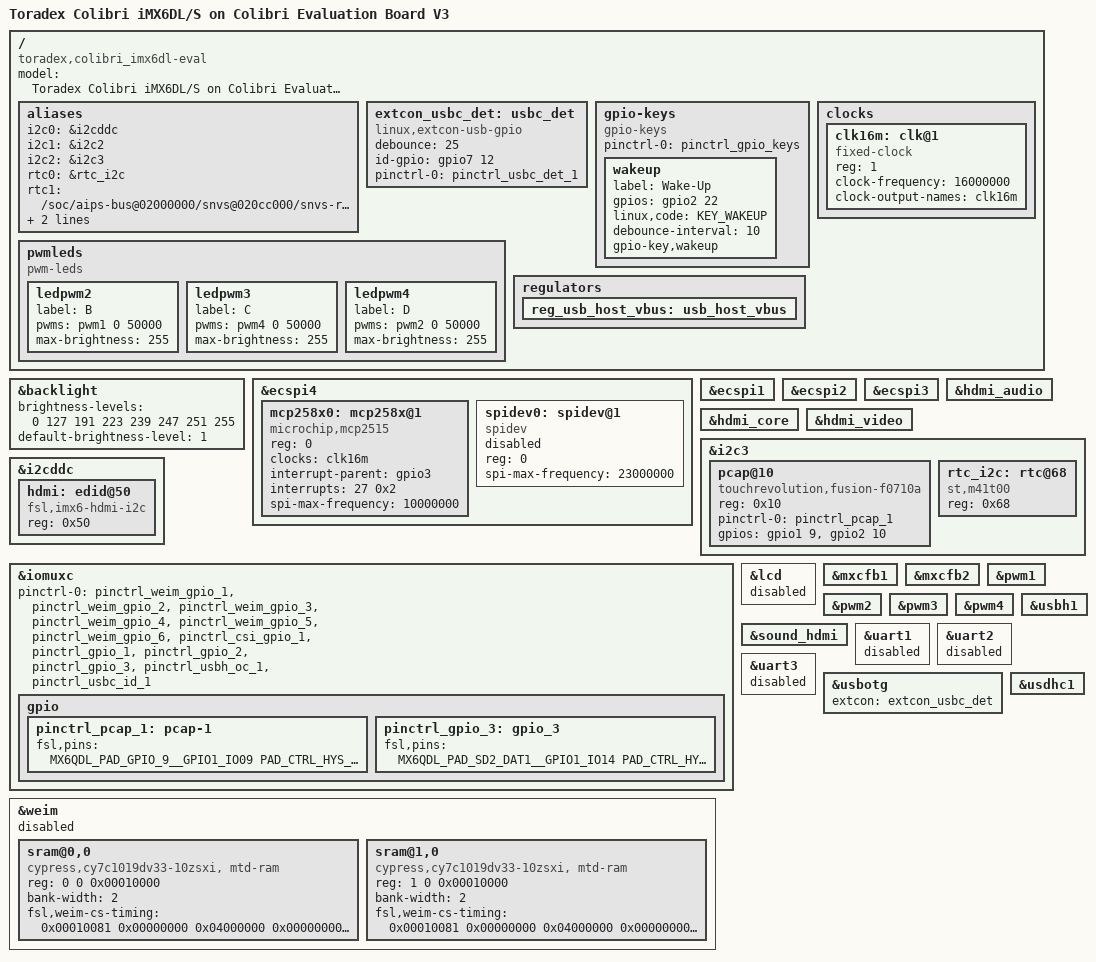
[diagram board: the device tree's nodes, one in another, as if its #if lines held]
/*
 * Copyright 2014-2015 Toradex AG
 * Copyright 2012 Freescale Semiconductor, Inc.
 * Copyright 2011 Linaro Ltd.
 *
 * The code contained herein is licensed under the GNU General Public
 * License. You may obtain a copy of the GNU General Public License
 * Version 2 or later at the following locations:
 *
 * http://www.opensource.org/licenses/gpl-license.html
 * http://www.gnu.org/copyleft/gpl.html
 */

/dts-v1/;

#include <dt-bindings/input/input.h>
#include <dt-bindings/interrupt-controller/irq.h>
#include "imx6dl.dtsi"
#include "imx6qdl-colibri.dtsi"

/* Add the following define if you connect a Fusion display with a capacitive
   touch controller */
/* #define PCAP */

/ {
	model = "Toradex Colibri iMX6DL/S on Colibri Evaluation Board V3";
	compatible = "toradex,colibri_imx6dl-eval", "toradex,colibri_imx6dl", "fsl,imx6dl";

	aliases {
		i2c0 = &i2cddc;
		i2c1 = &i2c2;
		i2c2 = &i2c3;
	};

	aliases {
		rtc0 = &rtc_i2c;
		rtc1 = "/soc/aips-bus@02000000/snvs@020cc000/snvs-rtc-lp@34";
	};

	aliases {
		/* the following, together with kernel patches, forces a fixed assignment
		   between device id and usdhc controller */
		/* i.e. the eMMC on usdhc3 will be /dev/mmcblk0 */
		mmc0 = &usdhc3; /* eMMC */
		mmc1 = &usdhc1; /* MMC 4bit slot */
	};

	extcon_usbc_det: usbc_det {
		compatible = "linux,extcon-usb-gpio";
		debounce = <25>;
		id-gpio = <&gpio7 12 GPIO_ACTIVE_HIGH>;
		pinctrl-names = "default";
		pinctrl-0 = <&pinctrl_usbc_det_1>;
	};

	gpio-keys {
		compatible = "gpio-keys";
		pinctrl-names = "default";
		pinctrl-0 = <&pinctrl_gpio_keys>;

		wakeup {
			label = "Wake-Up";
			gpios = <&gpio2 22 GPIO_ACTIVE_HIGH>;
			linux,code = <KEY_WAKEUP>;
			debounce-interval = <10>;
			gpio-key,wakeup;
		};
	};

	pwmleds {
		compatible = "pwm-leds";
#ifndef PCAP
		ledpwm2 {
			label = "PWM<B>";
			pwms = <&pwm1 0 50000>;
			max-brightness = <255>;
		};

		ledpwm3 {
			label = "PWM<C>";
			pwms = <&pwm4 0 50000>;
			max-brightness = <255>;
		};
#endif
		ledpwm4 {
			label = "PWM<D>";
			pwms = <&pwm2 0 50000>;
			max-brightness = <255>;
		};
	};

	regulators {
		reg_usb_host_vbus: usb_host_vbus {
			status = "okay";
		};
	};
};

&backlight {
#if 0 /* PWM polarity: if 1 is brightest */
#if 0 /* Fusion 7 needs 10kHz PWM frequency */
	pwms = <&pwm3 0 100000>;
#endif
	brightness-levels = <0 4 8 16 32 64 128 255>;
	default-brightness-level = <6>;
#else /* PWM plarity: if 0 is brightest */
	brightness-levels = <0 127 191 223 239 247 251 255>;
	default-brightness-level = <1>;
#endif
	status = "okay";
};

/ {
	clocks {
		/* fixed crystal dedicated to mpc258x */
		clk16m: clk@1 {
			compatible = "fixed-clock";
			reg=<1>;
			#clock-cells = <0>;
			clock-frequency = <16000000>;
			clock-output-names = "clk16m";
		};
	};
};

/* Colibri SPI */
&ecspi4 {
	status = "okay";
	mcp258x0: mcp258x@1 {
		compatible = "microchip,mcp2515";
		reg = <0>;
		clocks = <&clk16m>;
		interrupt-parent = <&gpio3>;
		interrupts = <27 0x2>;
		spi-max-frequency = <10000000>;
		status = "okay";
	};
	spidev0: spidev@1 {
		compatible = "spidev";
		reg = <0>;
		spi-max-frequency = <23000000>;
		status = "disabled";
	};
};
/* connect device to additional SPI bus */
&ecspi1 {
 status = "okay";
};
&ecspi2 {
 status = "okay";
};
&ecspi3 {
 status = "okay";
};


&hdmi_audio {
	status = "okay";
};

&hdmi_core {
	status = "okay";
};

&hdmi_video {
	status = "okay";
};


/*
 * I2C: I2C3_SDA/SCL on SODIMM 194/196 (e.g. RTC on carrier
 * board)
 */
&i2c3 {
	status = "okay";
#ifdef PCAP /* not standard pinout, disable PWM<B>, PWM<C> */
	pcap@10 {
		/* TouchRevolution Fusion 7 and 10 multi-touch controller */
		compatible = "touchrevolution,fusion-f0710a";
		reg = <0x10>;
		pinctrl-names = "default";
		pinctrl-0 = <&pinctrl_pcap_1>;
		gpios = <&gpio1  9 0 /* SODIMM 28, Pen down interrupt */
			 &gpio2 10 0 /* SODIMM 30, Reset */
			>;
	};
#endif
	/* M41T0M6 real time clock on carrier board */
	rtc_i2c: rtc@68 {
		compatible = "st,m41t00";
		reg = <0x68>;
	};
};

/*
 * DDC_I2C: I2C2_SDA/SCL on extension connector pin 15/16
 */
&i2cddc {
	status = "okay";

	hdmi: edid@50 {
		compatible = "fsl,imx6-hdmi-i2c";
		reg = <0x50>;
	};
};

&iomuxc {
	/*
	 * Mux all pins which are unused to be GPIOs
	 * so they are ready for export to user space
	 */
	pinctrl-names = "default";
	pinctrl-0 = <&pinctrl_weim_gpio_1 &pinctrl_weim_gpio_2
	             &pinctrl_weim_gpio_3 &pinctrl_weim_gpio_4
	             &pinctrl_weim_gpio_5 &pinctrl_weim_gpio_6
	             &pinctrl_csi_gpio_1
	             &pinctrl_gpio_1
	             &pinctrl_gpio_2 /*may cause conflict with can1*/
               &pinctrl_gpio_3  /*THIS NODE IS DEFINED BY ME*/
	             &pinctrl_usbh_oc_1 &pinctrl_usbc_id_1>;

	gpio {
		pinctrl_pcap_1: pcap-1 {
			fsl,pins = <
				MX6QDL_PAD_GPIO_9__GPIO1_IO09	PAD_CTRL_HYS_PD /* SODIMM 28 */
				MX6QDL_PAD_SD4_DAT2__GPIO2_IO10	PAD_CTRL_HYS_PD /* SODIMM 30 */
			>;
		};
    /* this node configure other pin to gpio*/
    pinctrl_gpio_3: gpio_3 {
      fsl,pins = <
        MX6QDL_PAD_SD2_DAT1__GPIO1_IO14	PAD_CTRL_HYS_PU    /* conflict with weim (already disabled)*/
        MX6QDL_PAD_SD4_DAT6__GPIO2_IO14	PAD_CTRL_HYS_PU    /* conflict with uart (already disabled)*/
        MX6QDL_PAD_SD4_DAT5__GPIO2_IO13	PAD_CTRL_HYS_PU    /* conflict with uart (already disabled)*/
        MX6QDL_PAD_SD4_DAT7__GPIO2_IO15	PAD_CTRL_HYS_PU    /* conflict with uart (already disabled)*/
        MX6QDL_PAD_SD4_DAT4__GPIO2_IO12	PAD_CTRL_HYS_PU    /* conflict with uart (already disabled)*/
        MX6QDL_PAD_NANDF_D7__GPIO2_IO07	PAD_CTRL_HYS_PU
        MX6QDL_PAD_NANDF_D6__GPIO2_IO06 PAD_CTRL_HYS_PU
        MX6QDL_PAD_EIM_RW__GPIO2_IO26 PAD_CTRL_HYS_PU     /* conflict with weim (already disabled)*/
        MX6QDL_PAD_EIM_OE__GPIO2_IO25 PAD_CTRL_HYS_PU     /* conflict with weim (already disabled)*/

        MX6QDL_PAD_EIM_DA8__GPIO3_IO08	PAD_CTRL_HYS_PU   /* pins below are conflict with weim (already disabled)*/
        MX6QDL_PAD_EIM_DA0__GPIO3_IO00	PAD_CTRL_HYS_PU
        MX6QDL_PAD_EIM_DA9__GPIO3_IO09	PAD_CTRL_HYS_PU
        MX6QDL_PAD_EIM_DA1__GPIO3_IO01	PAD_CTRL_HYS_PU
        MX6QDL_PAD_EIM_DA10__GPIO3_IO10	PAD_CTRL_HYS_PU
        MX6QDL_PAD_EIM_DA2__GPIO3_IO02	PAD_CTRL_HYS_PU
        MX6QDL_PAD_EIM_DA11__GPIO3_IO11	PAD_CTRL_HYS_PU
        MX6QDL_PAD_EIM_DA3__GPIO3_IO03	PAD_CTRL_HYS_PU
        MX6QDL_PAD_EIM_DA12__GPIO3_IO12	PAD_CTRL_HYS_PU
        MX6QDL_PAD_EIM_DA4__GPIO3_IO04	PAD_CTRL_HYS_PU
        MX6QDL_PAD_EIM_DA13__GPIO3_IO13	PAD_CTRL_HYS_PU
        MX6QDL_PAD_EIM_DA5__GPIO3_IO05	PAD_CTRL_HYS_PU
        MX6QDL_PAD_EIM_DA14__GPIO3_IO14	PAD_CTRL_HYS_PU
        MX6QDL_PAD_EIM_DA6__GPIO3_IO06	PAD_CTRL_HYS_PU
        MX6QDL_PAD_EIM_DA15__GPIO3_IO15	PAD_CTRL_HYS_PU
        MX6QDL_PAD_EIM_DA7__GPIO3_IO07	PAD_CTRL_HYS_PU  /*All the pins above are conflicted with weim (disabled)*/
        MX6QDL_PAD_EIM_EB0__GPIO2_IO28	PAD_CTRL_HYS_PU
        MX6QDL_PAD_EIM_D19__GPIO3_IO19	PAD_CTRL_HYS_PU  /* conflict with uart (already disabled)*/
        MX6QDL_PAD_EIM_D23__GPIO3_IO23	PAD_CTRL_HYS_PU  /* conflict with uart (already disabled)*/

        MX6QDL_PAD_DISP0_DAT9__GPIO4_IO30	PAD_CTRL_HYS_PU  /* MX6QDL_PAD_DISP0_DAT0 -- MX6QDL_PAD_DISP0_DAT17 are conflicted with lcd(disabled) */
        MX6QDL_PAD_DISP0_DAT11__GPIO5_IO05	PAD_CTRL_HYS_PU
        MX6QDL_PAD_DISP0_DAT16__GPIO5_IO10	PAD_CTRL_HYS_PU
        MX6QDL_PAD_DISP0_DAT17__GPIO5_IO11	PAD_CTRL_HYS_PU
        MX6QDL_PAD_DISP0_DAT8__GPIO4_IO29	  PAD_CTRL_HYS_PU
        MX6QDL_PAD_DISP0_DAT15__GPIO5_IO09	PAD_CTRL_HYS_PU
        MX6QDL_PAD_DISP0_DAT14__GPIO5_IO08	PAD_CTRL_HYS_PU
        MX6QDL_PAD_DISP0_DAT13__GPIO5_IO07	PAD_CTRL_HYS_PU


        MX6QDL_PAD_DI0_DISP_CLK__GPIO4_IO16	PAD_CTRL_HYS_PU
        MX6QDL_PAD_DI0_PIN2__GPIO4_IO18	PAD_CTRL_HYS_PU
        MX6QDL_PAD_DI0_PIN3__GPIO4_IO19	PAD_CTRL_HYS_PU   /* pins above are all conflicted with lcd(disabled) */

        MX6QDL_PAD_CSI0_DATA_EN__GPIO5_IO20 PAD_CTRL_HYS_PU  /* pins below are all conflicted with weim(disabled) */
        MX6QDL_PAD_CSI0_VSYNC__GPIO5_IO21 PAD_CTRL_HYS_PU
        MX6QDL_PAD_CSI0_DAT4__GPIO5_IO22 PAD_CTRL_HYS_PU
        MX6QDL_PAD_CSI0_DAT5__GPIO5_IO23 PAD_CTRL_HYS_PU
        MX6QDL_PAD_CSI0_DAT6__GPIO5_IO24 PAD_CTRL_HYS_PU
        MX6QDL_PAD_CSI0_DAT7__GPIO5_IO25 PAD_CTRL_HYS_PU
        MX6QDL_PAD_CSI0_DAT12__GPIO5_IO30 PAD_CTRL_HYS_PU
        MX6QDL_PAD_CSI0_DAT11__GPIO5_IO29 PAD_CTRL_HYS_PU

        MX6QDL_PAD_CSI0_DAT13__GPIO5_IO31 PAD_CTRL_HYS_PU
        MX6QDL_PAD_CSI0_DAT14__GPIO6_IO00 PAD_CTRL_HYS_PU
        MX6QDL_PAD_CSI0_DAT15__GPIO6_IO01 PAD_CTRL_HYS_PU
        MX6QDL_PAD_CSI0_DAT16__GPIO6_IO02 PAD_CTRL_HYS_PU
        MX6QDL_PAD_CSI0_DAT17__GPIO6_IO03 PAD_CTRL_HYS_PU
        MX6QDL_PAD_CSI0_DAT18__GPIO6_IO04 PAD_CTRL_HYS_PU
        MX6QDL_PAD_CSI0_DAT19__GPIO6_IO05 PAD_CTRL_HYS_PU  /* pins above are all conflicted with weim */
        MX6QDL_PAD_SD4_CMD__GPIO7_IO09 PAD_CTRL_HYS_PU
        MX6QDL_PAD_SD4_CLK__GPIO7_IO10 PAD_CTRL_HYS_PU     /* both are conflicted with uart3(disabled) */

      >;
    };
	};
};

&lcd {
/*status = "okay";*/
status = "disabled";
};

&mxcfb1 {
	status = "okay";
};

&mxcfb2 {
	status = "okay";
};

#ifndef PCAP
&pwm1 {
	status = "okay";
};
#endif

&pwm2 {
	status = "okay";
};

&pwm3 {
	status = "okay";
};

#ifndef PCAP
&pwm4 {
	status = "okay";
};
#endif

&sound_hdmi {
	status = "okay";
};

&uart1 {
/*status = "okay";*/
status = "disabled";
};

&uart2 {
/*status = "okay";*/
status = "disabled";
#if 0
	linux,rs485-enabled-at-boot-time;
#endif
};

&uart3 {
/*status = "okay";*/
status = "disabled";
};

&usbh1 {
	status = "okay";
};

&usbotg {
	status = "okay";
	extcon = <&extcon_usbc_det>;
};

/* MMC */
&usdhc1 {
	status = "okay";
};

&weim {
  /* disable this node to avoid pin mux conflicts */
	/*status = "okay";*/
  status = "disabled";
	/* weim memory map: 32MB on CS0, 32MB on CS1, 32MB on CS2 */
	ranges = <0 0 0x08000000 0x02000000
	          1 0 0x0a000000 0x02000000
	          2 0 0x0c000000 0x02000000>;
	/* SRAM on CS0 */
	sram@0,0 {
		compatible = "cypress,cy7c1019dv33-10zsxi, mtd-ram";
		reg = <0 0 0x00010000>;
		#address-cells = <1>;
		#size-cells = <1>;
		bank-width = <2>;
		fsl,weim-cs-timing = <0x00010081 0x00000000 0x04000000
				0x00000000 0x04000040 0x00000000>;
	};
	/* SRAM on CS1 */
	sram@1,0 {
		compatible = "cypress,cy7c1019dv33-10zsxi, mtd-ram";
		reg = <1 0 0x00010000>;
		#address-cells = <1>;
		#size-cells = <1>;
		bank-width = <2>;
		fsl,weim-cs-timing = <0x00010081 0x00000000 0x04000000
				0x00000000 0x04000040 0x00000000>;
	};
};
